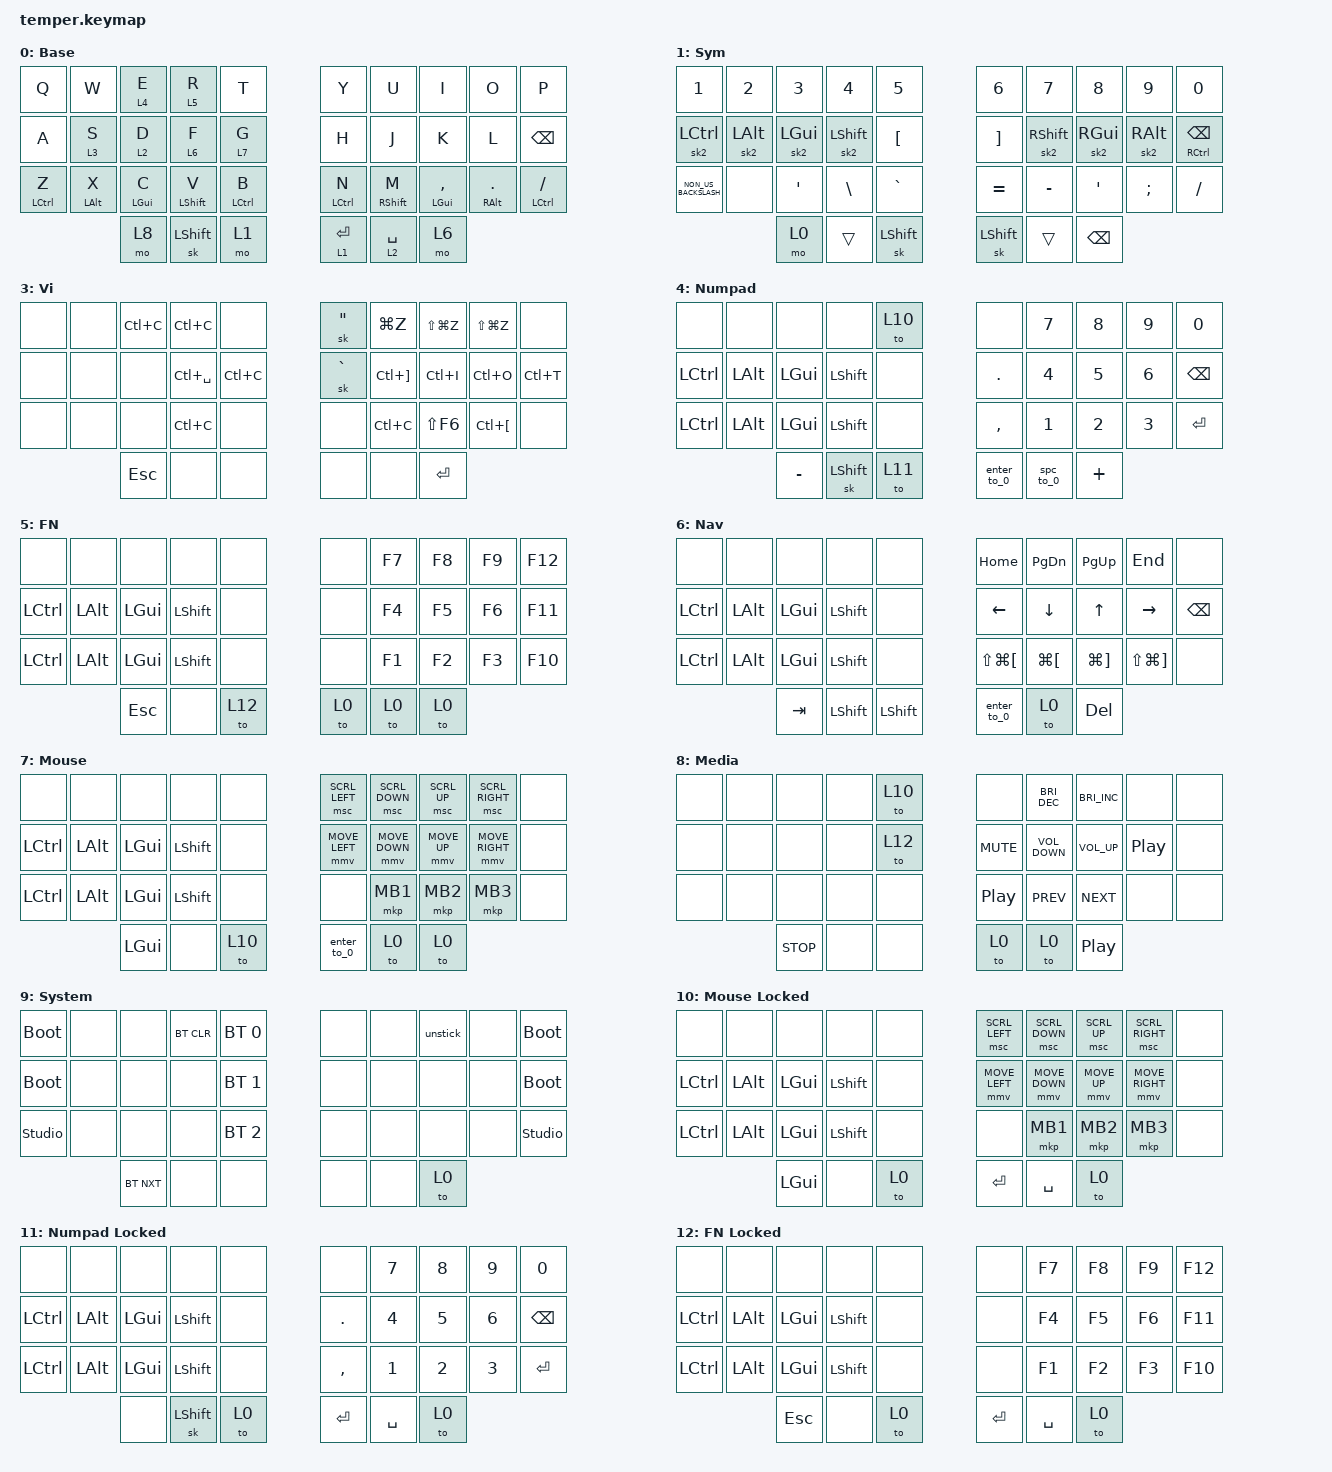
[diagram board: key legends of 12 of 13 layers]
/*
 * FunkeeB Temper keymap, ported from kb (urchin-zmk-firmware).
 * Based on the Urchin keymap: Copyright (c) 2020 duckyb
 * SPDX-License-Identifier: MIT
 *
 * Plain ZMK devicetree for ZMK Studio and Nick Coutsos' ZMK Keymap Editor.
 * Layers 0-12 match kb; Numpad Locked, FN Locked and Symbols occupy 13-15.
 * Urchin positions 0-29 map directly; thumbs 30-33 become 31-34.
 * Temper's extra outer thumbs (30 and 35) provide per-layer utility actions.
 */

#include <behaviors.dtsi>
#include <dt-bindings/zmk/bt.h>
#include <dt-bindings/zmk/keys.h>
#include <dt-bindings/zmk/pointing.h>

&sk {
    quick-release;
    lazy;
    release-after-ms = <1000>;
};

&mt {
    flavor = "balanced";
    tapping-term-ms = <260>;
    hold-while-undecided;
    require-prior-idle-ms = <100>;
};

/ {
    behaviors {
        qt: quick_tap {
            compatible = "zmk,behavior-hold-tap";
            #binding-cells = <2>;
            flavor = "hold-preferred";
            tapping-term-ms = <200>;
            quick-tap-ms = <200>;
            bindings = <&kp>, <&kp>;
        };

        /* Include the extra opposite-hand thumb in each hand's hold triggers. */

        homerow_left: homerow_left {
            compatible = "zmk,behavior-hold-tap";
            #binding-cells = <2>;
            bindings = <&kp>, <&kp>;

            tapping-term-ms = <350>;
            require-prior-idle-ms = <100>;
            flavor = "balanced";
            hold-trigger-key-positions = <5 6 7 8 9 15 16 17 18 19 25 26 27 28 29 33 34 35>;
            hold-trigger-on-release;
        };

        homerow_right: homerow_right {
            compatible = "zmk,behavior-hold-tap";
            #binding-cells = <2>;
            bindings = <&kp>, <&kp>;

            tapping-term-ms = <280>;
            require-prior-idle-ms = <150>;
            flavor = "balanced";
            hold-trigger-on-release;
            hold-trigger-key-positions = <0 1 2 3 4 10 11 12 13 14 20 21 22 23 24 30 31 32>;
        };

        tap_left: tap_left {
            compatible = "zmk,behavior-hold-tap";
            #binding-cells = <2>;
            bindings = <&mo>, <&kp>;

            tapping-term-ms = <280>;
            flavor = "balanced";
            hold-trigger-key-positions = <5 6 7 8 9 15 16 17 18 19 25 26 27 28 29 33 34 35>;
            hold-trigger-on-release;
        };

        tap_right: tap_right {
            compatible = "zmk,behavior-hold-tap";
            #binding-cells = <2>;
            bindings = <&mo>, <&kp>;

            tapping-term-ms = <280>;
            require-prior-idle-ms = <50>;
            flavor = "balanced";
            hold-trigger-key-positions = <0 1 2 3 4 10 11 12 13 14 20 21 22 23 24 30 31 32>;
            hold-trigger-on-release;
        };

        master_key: master_key {
            compatible = "zmk,behavior-hold-tap";
            #binding-cells = <2>;
            bindings = <&mo>, <&kp>;

            tapping-term-ms = <350>;
            flavor = "tap-preferred";
            hold-trigger-key-positions = <16 17 7 18 28 27 26 6 8 12 13 22 23 15 5 25 14 24 4 3 2 19 11 10 21 1 20 29 0 9>;
            hold-trigger-on-release;
        };

        macro_layers: macro_layers {
            compatible = "zmk,behavior-hold-tap";
            #binding-cells = <2>;
            bindings = <&tog>, <&sl>;

            tapping-term-ms = <280>;
            require-prior-idle-ms = <80>;
            flavor = "balanced";
            hold-trigger-on-release;
            hold-trigger-key-positions = <13 12 6 7 8 16 17 18 27 28 26 9 22 23>;
        };

        sk2: sk2 {
            compatible = "zmk,behavior-sticky-key";
            #binding-cells = <1>;
            bindings = <&kp>;
            release-after-ms = <1500>;
            quick-release;
            ignore-modifiers;
        };

        tap_left_strict: tap_left_strict {
            compatible = "zmk,behavior-hold-tap";
            #binding-cells = <2>;
            bindings = <&mo>, <&kp>;

            tapping-term-ms = <260>;
            require-prior-idle-ms = <100>;
            flavor = "tap-preferred";
            hold-trigger-key-positions = <5 6 7 8 9 15 16 17 18 19 25 26 27 28 29 33 34 35>;
            hold-trigger-on-release;
        };
    };

    macros {
        unstick: unstick {
            compatible = "zmk,behavior-macro";
            #binding-cells = <0>;
            bindings = <&kp LSHIFT &kp RSHIFT &kp LCTRL &kp RCTRL &kp LALT &kp RALT &kp LGUI &kp RGUI>;
        };

        shifted: shifted {
            compatible = "zmk,behavior-macro-one-param";
            #binding-cells = <1>;
            bindings =
                <&macro_press>,
                <&kp LEFT_SHIFT>,
                <&macro_tap>,
                <&macro_param_1to1 &kp MACRO_PLACEHOLDER>,
                <&macro_release>,
                <&kp LEFT_SHIFT>;
        };

        spc_to_0: spc_to_0 {
            compatible = "zmk,behavior-macro";
            #binding-cells = <0>;
            bindings = <&to 0 &kp SPACE>;
        };

        enter_to_0: enter_to_0 {
            compatible = "zmk,behavior-macro";
            #binding-cells = <0>;
            bindings = <&to 0 &kp ENTER>;
        };
    };

    /* kb combos, with targets and layer scopes matched to this keymap. */

    combos {
        compatible = "zmk,combos";

        esc {
            bindings = <&kp ESCAPE>;
            key-positions = <16 17>;
            require-prior-idle-ms = <150>;
            layers = <0>;
        };

        jk_to_base {
            bindings = <&to 0>;
            key-positions = <16 17>;
            timeout-ms = <50>;
            layers = <2 3 4 5 6 7 8 9 10 11 12>;
        };

        ctrlspace {
            bindings = <&kp LC(SPACE)>;
            key-positions = <7 8>;
            require-prior-idle-ms = <350>;
            timeout-ms = <50>;
            layers = <0>;
        };

        system_tog {
            bindings = <&tog 9>;
            key-positions = <1 11 21>;
            require-prior-idle-ms = <250>;
            layers = <0 9>;
        };

        reset_base {
            bindings = <&to 0>;
            key-positions = <0 1 2 3>;
        };

        fn_tap {
            bindings = <&mo 5>;
            key-positions = <2 1>;
            layers = <0 5>;
            require-prior-idle-ms = <280>;
            timeout-ms = <30>;
        };

        media_tap {
            bindings = <&mo 8>;
            key-positions = <24 23>;
            layers = <0 8>;
            timeout-ms = <30>;
            require-prior-idle-ms = <280>;
        };

        tab {
            bindings = <&kp TAB>;
            key-positions = <15 16>;
            timeout-ms = <100>;
            require-prior-idle-ms = <30>;
            layers = <0 1 4 11>;
        };

        sys2 {
            bindings = <&tog 9>;
            key-positions = <8 18 28>;
            layers = <0 9>;
        };

        mouse {
            bindings = <&mo 7>;
            key-positions = <22 21>;
            timeout-ms = <50>;
            require-prior-idle-ms = <280>;
            layers = <0>;
        };

        media_tog {
            bindings = <&tog 8>;
            key-positions = <23 22 24>;
            layers = <0 8>;
            timeout-ms = <50>;
            require-prior-idle-ms = <280>;
        };

        altgui {
            bindings = <&sk LA(LGUI)>;
            key-positions = <26 27 28>;
            timeout-ms = <100>;
            require-prior-idle-ms = <280>;
            layers = <0>;
        };

        alt_ctrl_gui {
            bindings = <&sk LA(LC(LGUI))>;
            key-positions = <26 27 28>;
            layers = <2>;
        };

        mouse2 {
            bindings = <&mo 7>;
            key-positions = <23 22>;
            layers = <0>;
        };

        enter {
            bindings = <&kp ENTER>;
            key-positions = <7 6>;
            timeout-ms = <50>;
            require-prior-idle-ms = <280>;
            layers = <0>;
        };

        brace {
            bindings = <&kp LEFT_BRACKET>;
            key-positions = <15 6>;
            timeout-ms = <50>;
            require-prior-idle-ms = <280>;
            layers = <0>;
        };

        brace2 {
            bindings = <&kp RIGHT_BRACKET>;
            key-positions = <16 7>;
            timeout-ms = <50>;
            require-prior-idle-ms = <250>;
            layers = <0>;
        };

        /* Short chords after a typing pause reduce accidental re/te triggers. */

        re_left_bracket {
            bindings = <&kp LEFT_BRACKET>;
            key-positions = <3 2>;
            timeout-ms = <35>;
            require-prior-idle-ms = <150>;
            layers = <0>;
        };

        te_right_bracket {
            bindings = <&kp RIGHT_BRACKET>;
            key-positions = <4 2>;
            timeout-ms = <35>;
            require-prior-idle-ms = <150>;
            layers = <0>;
        };

        bksp {
            bindings = <&kp BACKSPACE>;
            key-positions = <5 6>;
            timeout-ms = <50>;
            require-prior-idle-ms = <250>;
            layers = <0 1>;
        };
    };

    keymap {
        compatible = "zmk,keymap";

        base_layer {
            display-name = "Base";
            bindings = <
&kp Q                  &kp W                 &tap_left_strict 4 E  &tap_left_strict 5 R        &kp T                    &kp Y                   &kp U                    &kp I                          &kp O                       &kp P
&kp A                  &tap_left 3 S         &tap_left 2 D         &tap_left 6 F               &tap_left_strict 7 G     &kp H                   &kp J                    &kp K                          &kp L                       &kp BACKSPACE
&homerow_left LCTRL Z  &homerow_left LALT X  &homerow_left LGUI C  &homerow_left LEFT_SHIFT V  &homerow_left LCTRL B    &homerow_right LCTRL N  &homerow_right RSHIFT M  &homerow_right LEFT_GUI COMMA  &homerow_right RALT PERIOD  &homerow_right LCTRL SLASH
                                             &mo 8                 &sk LEFT_SHIFT              &mo 1                    &master_key 1 ENTER     &master_key 2 SPACE      &mo 6
            >;
        };

        sym_layer {
            display-name = "Sym";
            bindings = <
&kp N1                &kp N2     &kp N3     &kp N4         &kp N5            &kp N6          &kp N7      &kp N8         &kp N9         &kp N0
&sk2 LCTRL            &sk2 LALT  &sk2 LGUI  &sk2 LSHFT     &kp LBKT          &kp RBKT        &sk2 RSHFT  &sk2 RGUI      &sk2 RALT      &homerow_right RCTRL BACKSPACE
&kp NON_US_BACKSLASH  &none      &kp APOS   &kp BACKSLASH  &kp GRAVE         &kp EQUAL       &kp MINUS   &kp SQT        &kp SEMICOLON  &kp FSLH
                                 &mo 0      &trans         &sk LEFT_SHIFT    &sk LEFT_SHIFT  &trans      &kp BACKSPACE
            >;
        };

        master_layer {
            display-name = "Master";
            bindings = <
&none  &none          &none                 &kp LG(MINUS)         &kp LG(EQUAL)               &kp LG(A)      &kp LG(C)          &kp LG(V)      &kp LG(X)      &kp LG(A)
&none  &kp LG(SPACE)  &kp LA(LC(LEFT_GUI))  &sk LA(LC(LEFT_GUI))  &sk LS(LA(LC(LEFT_GUI)))    &kp LG(TILDE)  &kp ENTER          &kp BACKSPACE  &kp TAB        &kp LC(LEFT_BRACKET)
&none  &none          &kp LG(SPACE)         &kp LS(LG(SPACE))     &kp LG(LS(J))               &none          &kp LA(BACKSPACE)  &kp DELETE     &kp LG(ENTER)  &none
                      &caps_word            &kp LEFT_SHIFT        &kp LEFT_GUI                &kp LALT       &kp LCTRL          &kp ESC
            >;
        };

        vi_layer {
            display-name = "Vi";
            bindings = <
&none  &none  &kp LC(C)  &kp LC(C)      &none        &sk DOUBLE_QUOTES  &kp LG(Z)              &kp LS(LG(Z))  &kp LS(LG(Z))         &none
&none  &none  &none      &kp LC(SPACE)  &kp LC(C)    &sk GRAVE          &kp LC(RIGHT_BRACKET)  &kp LC(I)      &kp LC(O)             &kp LC(T)
&none  &none  &none      &kp LC(C)      &none        &none              &kp LC(C)              &kp LS(F6)     &kp LC(LEFT_BRACKET)  &none
              &kp ESC    &none          &none        &none              &none                  &kp ENTER
            >;
        };

        numpad_layer {
            display-name = "Numpad";
            bindings = <
&none      &none     &none      &none           &to 10    &none        &kp N7     &kp N8    &kp N9  &kp N0
&kp LCTRL  &kp LALT  &kp LGUI   &kp LSHFT       &none     &kp DOT      &kp N4     &kp N5    &kp N6  &kp BSPC
&kp LCTRL  &kp LALT  &kp LGUI   &kp LSHFT       &none     &kp COMMA    &kp N1     &kp N2    &kp N3  &kp ENTER
                     &kp MINUS  &sk LEFT_SHIFT  &to 11    &enter_to_0  &spc_to_0  &kp PLUS
            >;
        };

        fn_layer {
            display-name = "FN";
            bindings = <
&none      &none     &none     &none      &none     &none  &kp F7  &kp F8  &kp F9  &kp F12
&kp LCTRL  &kp LALT  &kp LGUI  &kp LSHFT  &none     &none  &kp F4  &kp F5  &kp F6  &kp F11
&kp LCTRL  &kp LALT  &kp LGUI  &kp LSHFT  &none     &none  &kp F1  &kp F2  &kp F3  &kp F10
                     &kp ESC   &none      &to 12    &to 0  &to 0   &to 0
            >;
        };

        nav_layer {
            display-name = "Nav";
            bindings = <
&none      &none     &none     &none           &none             &kp HOME                  &kp PAGE_DOWN         &kp PAGE_UP            &kp END                    &none
&kp LCTRL  &kp LALT  &kp LGUI  &kp LSHFT       &none             &kp LEFT                  &kp DOWN              &kp UP                 &kp RIGHT                  &kp BACKSPACE
&kp LCTRL  &kp LALT  &kp LGUI  &kp LSHFT       &none             &kp LS(LG(LEFT_BRACKET))  &kp LG(LEFT_BRACKET)  &kp LG(RIGHT_BRACKET)  &kp LS(LG(RIGHT_BRACKET))  &none
                     &kp TAB   &kp LEFT_SHIFT  &kp LEFT_SHIFT    &enter_to_0               &to 0                 &kp DELETE
            >;
        };

        mouse_layer {
            display-name = "Mouse";
            bindings = <
&none      &none     &none     &none      &none     &msc SCRL_LEFT  &msc SCRL_DOWN  &msc SCRL_UP  &msc SCRL_RIGHT  &none
&kp LCTRL  &kp LALT  &kp LGUI  &kp LSHFT  &none     &mmv MOVE_LEFT  &mmv MOVE_DOWN  &mmv MOVE_UP  &mmv MOVE_RIGHT  &none
&kp LCTRL  &kp LALT  &kp LGUI  &kp LSHFT  &none     &none           &mkp MB1        &mkp MB2      &mkp MB3         &none
                     &kp LGUI  &none      &to 10    &enter_to_0     &to 0           &to 0
            >;
        };

        media_layer {
            display-name = "Media";
            bindings = <
&none  &none  &none       &none  &to 10    &none             &kp C_BRIGHTNESS_DEC  &kp C_BRIGHTNESS_INC  &none             &none
&none  &none  &none       &none  &to 12    &kp C_MUTE        &kp C_VOLUME_DOWN     &kp C_VOLUME_UP       &kp C_PLAY_PAUSE  &none
&none  &none  &none       &none  &none     &kp C_PLAY_PAUSE  &kp C_PREV            &kp C_NEXT            &none             &none
              &kp C_STOP  &none  &none     &to 0             &to 0                 &kp C_PLAY_PAUSE
            >;
        };

        system_layer {
            display-name = "System";
            bindings = <
&bootloader     &none  &none       &bt BT_CLR  &bt BT_SEL 0    &none  &none  &unstick  &none  &bootloader
&bootloader     &none  &none       &none       &bt BT_SEL 1    &none  &none  &none     &none  &bootloader
&studio_unlock  &none  &none       &none       &bt BT_SEL 2    &none  &none  &none     &none  &studio_unlock
                       &bt BT_NXT  &none       &none           &none  &none  &to 0
            >;
        };

        /* Independent of Mouse so releasing the original &mo 8 keeps it locked. */

        mouse_locked_layer {
            display-name = "Mouse Locked";
            bindings = <
&none      &none     &none     &none      &none    &msc SCRL_LEFT  &msc SCRL_DOWN  &msc SCRL_UP  &msc SCRL_RIGHT  &none
&kp LCTRL  &kp LALT  &kp LGUI  &kp LSHFT  &none    &mmv MOVE_LEFT  &mmv MOVE_DOWN  &mmv MOVE_UP  &mmv MOVE_RIGHT  &none
&kp LCTRL  &kp LALT  &kp LGUI  &kp LSHFT  &none    &none           &mkp MB1        &mkp MB2      &mkp MB3         &none
                     &kp LGUI  &none      &to 0    &kp ENTER       &kp SPACE       &to 0
            >;
        };

        /* Dedicated copies survive release of the original &mo 5 / &mo 6. */

        numpad_locked_layer {
            display-name = "Numpad Locked";
            bindings = <
&none      &none     &none     &none           &none    &none      &kp N7     &kp N8  &kp N9  &kp N0
&kp LCTRL  &kp LALT  &kp LGUI  &kp LSHFT       &none    &kp DOT    &kp N4     &kp N5  &kp N6  &kp BSPC
&kp LCTRL  &kp LALT  &kp LGUI  &kp LSHFT       &none    &kp COMMA  &kp N1     &kp N2  &kp N3  &kp ENTER
                     &none     &sk LEFT_SHIFT  &to 0    &kp ENTER  &kp SPACE  &to 0
            >;
        };

        fn_locked_layer {
            display-name = "FN Locked";
            bindings = <
&none      &none     &none     &none      &none    &none      &kp F7     &kp F8  &kp F9  &kp F12
&kp LCTRL  &kp LALT  &kp LGUI  &kp LSHFT  &none    &none      &kp F4     &kp F5  &kp F6  &kp F11
&kp LCTRL  &kp LALT  &kp LGUI  &kp LSHFT  &none    &none      &kp F1     &kp F2  &kp F3  &kp F10
                     &kp ESC   &none      &to 0    &kp ENTER  &kp SPACE  &to 0
            >;
        };

        /* Original Temper/Miryoku symbols: left-hand symbols, right-hand modifiers. */
    };
};
